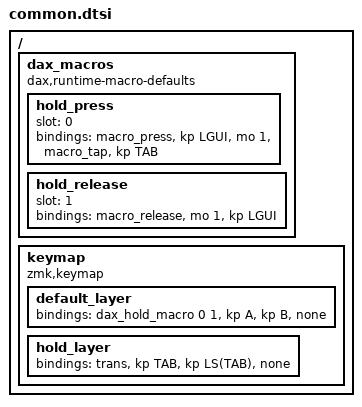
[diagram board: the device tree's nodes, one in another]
#include <behaviors.dtsi>
#include <behaviors/dax_macro.dtsi>
#include <behaviors/hold_macro.dtsi>
#include <dt-bindings/zmk/keys.h>
#include <dt-bindings/zmk/kscan_mock.h>

// The press macro holds LGUI and layer 1 and taps TAB; the release macro lets both go.
/ {
    dax_macros {
        compatible = "dax,runtime-macro-defaults";

        hold_press {
            slot = <0>;
            bindings = <&macro_press &kp LGUI &mo 1>, <&macro_tap &kp TAB>;
        };

        hold_release {
            slot = <1>;
            bindings = <&macro_release &mo 1 &kp LGUI>;
        };
    };

    keymap {
        compatible = "zmk,keymap";
        default_layer {
            bindings = <&dax_hold_macro 0 1 &kp A &kp B &none>;
        };
        hold_layer {
            bindings = <&trans &kp TAB &kp LS(TAB) &none>;
        };
    };
};
